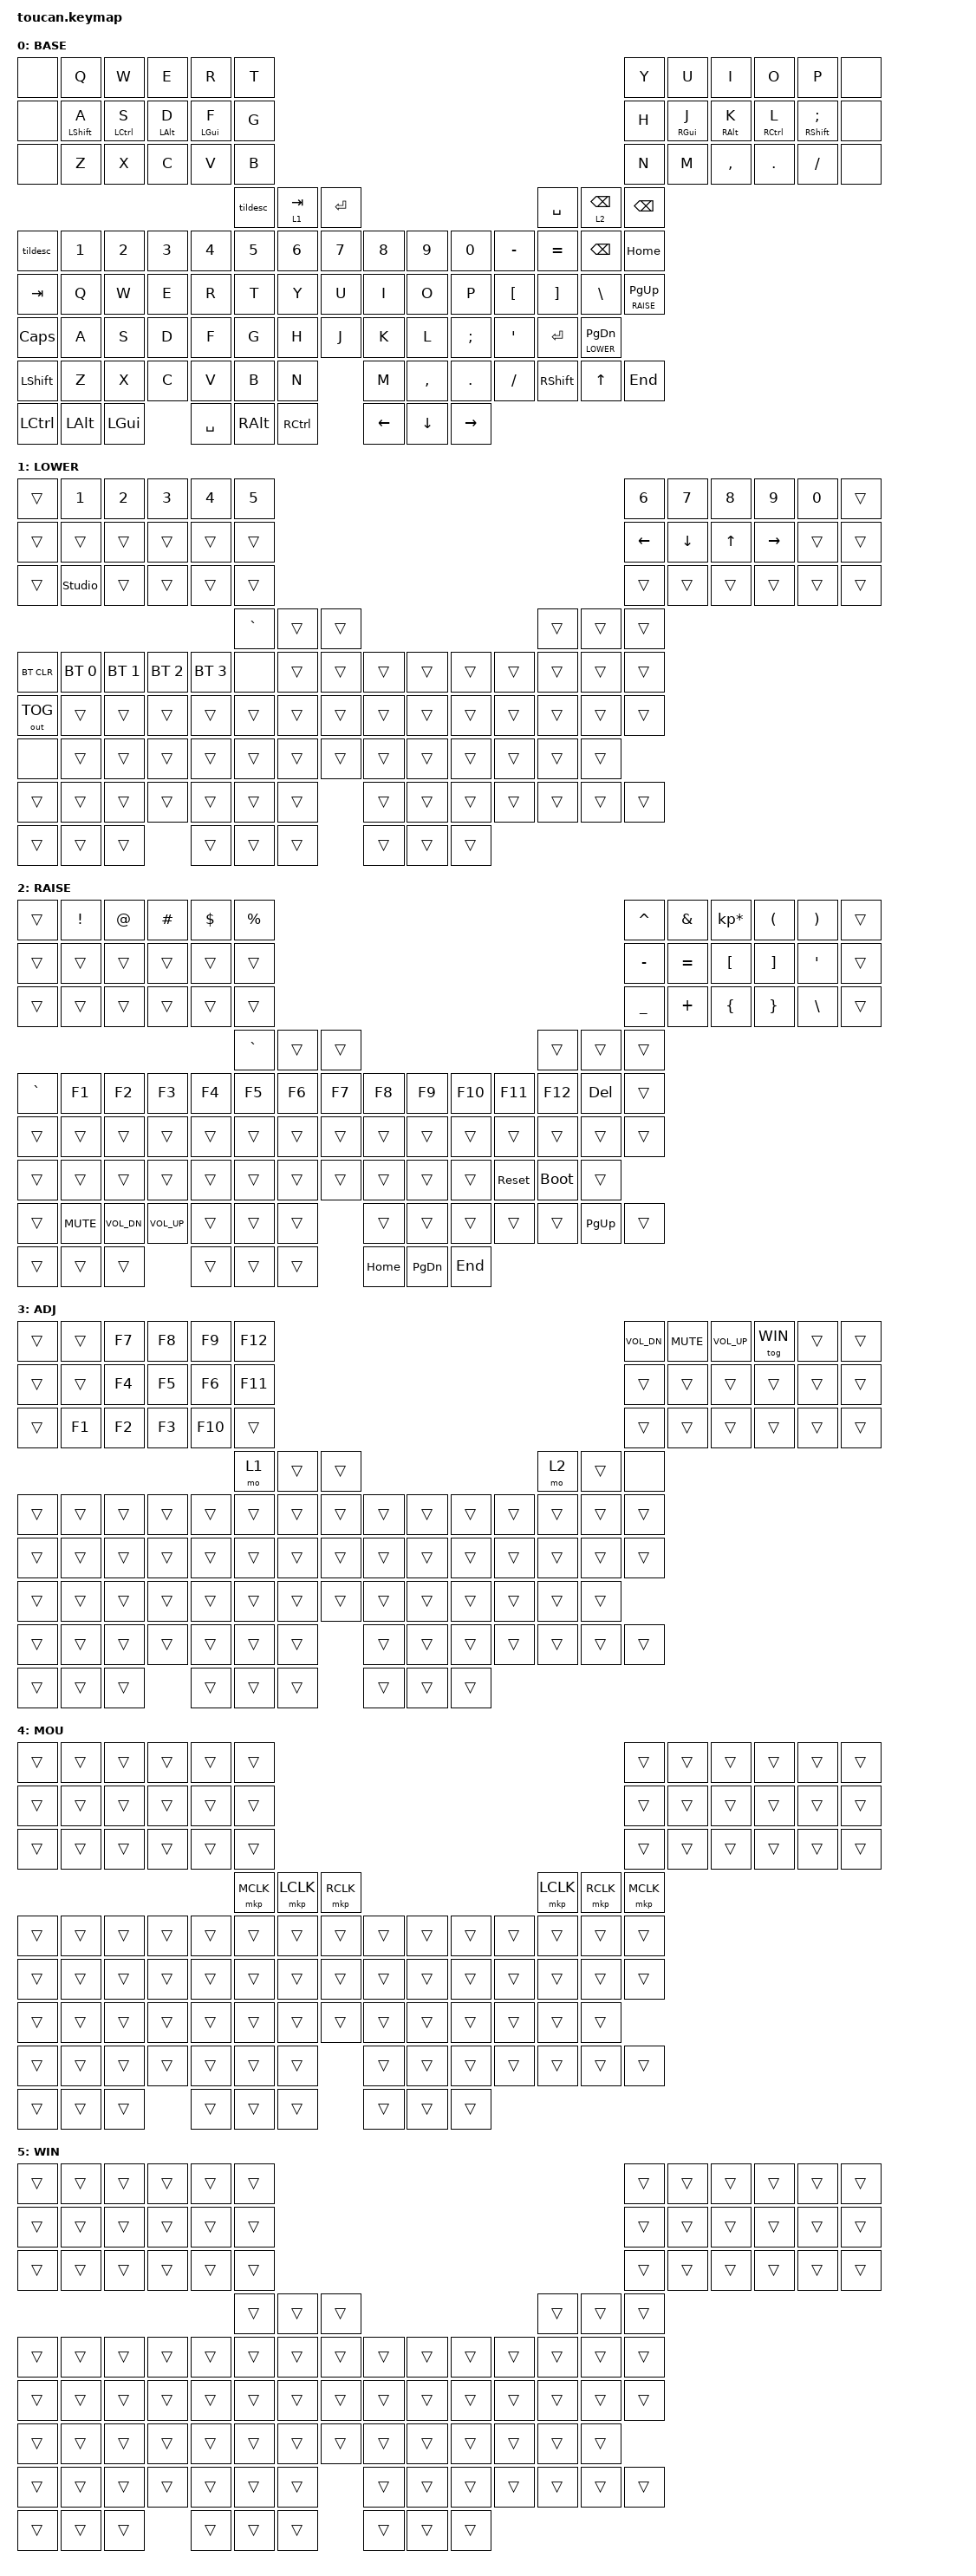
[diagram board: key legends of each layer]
#include <behaviors.dtsi>
#include <dt-bindings/zmk/keys.h>
#include <dt-bindings/zmk/bt.h>
#include <dt-bindings/zmk/outputs.h>

// Adding pointing.h to be able to right and middle click
// https://zmk.dev/docs/keymaps/behaviors/mouse-emulation
#include <dt-bindings/zmk/pointing.h>

#define BASE  0
#define LOWER 1
#define RAISE 2
#define ADJ   3
// Held automatically while a finger rests on the trackpad (is_touching_processor).
#define MOU   4
// Sticky toggle: swaps the trackpad's zoom/swipe shortcuts from macOS to Windows/Linux
// via the win_mode override on trackpad_listener. Otherwise transparent.
#define WIN   5


#define KEYS_L            0 1 2 3 4 5 12 13 14 15 16 17 24 25 26 27 28 29
#define KEYS_R            6 7 8 9 10 11 18 19 20 21 22 23 30 31 32 33 34 35
#define THUMBS            36 37 38 39 40 41
#define HRM_PRIOR_IDLE_MS 75

&lt {
  tapping-term-ms = <240>;
  flavor = "balanced";
  quick-tap-ms = <150>;
};

&mt {
  tapping-term-ms = <240>;
  flavor = "balanced";
  quick-tap-ms = <150>;
};

/ {
    conditional_layers {
        compatible = "zmk,conditional-layers";
        tri_layer {
            if-layers = <1 2>;
            then-layer = <3>;
        };
    };

    behaviors {
      // Testing urob's timeless home-row mods:
      // https://github.com/urob/zmk-config#timeless-homerow-mods
      // Cross-hand shortcuts can resolve immediately; same-hand shortcuts still
      // require holding past tapping-term-ms before pressing the next key.
      hrm_l: hrm_l {
        compatible = "zmk,behavior-hold-tap";
        #binding-cells = <2>;
        // How long a plain hold waits before becoming the modifier.
        // Cross-hand shortcuts can still resolve sooner via balanced + hold-trigger-key-positions.
        tapping-term-ms = <240>;
        bindings = <&kp>, <&kp>;
        flavor = "balanced";
        // If this HRM is tapped and quickly pressed again, keep the second press as a tap.
        // Useful for repeating letters without the second press becoming the modifier.
        quick-tap-ms = <150>;
        // If pressed within this window after a normal key, force a tap so fast typing stays immediate.
        // Lower this if intended HRM shifts/mods are blocked while typing quickly;
        // raise it if fast rolls accidentally trigger modifiers.
        require-prior-idle-ms = <HRM_PRIOR_IDLE_MS>;
        hold-trigger-key-positions = <KEYS_R THUMBS>;
        hold-trigger-on-release;
      };

      hrm_r: hrm_r {
        compatible = "zmk,behavior-hold-tap";
        #binding-cells = <2>;
        tapping-term-ms = <240>;
        bindings = <&kp>, <&kp>;
        flavor = "balanced";
        quick-tap-ms = <150>;
        require-prior-idle-ms = <HRM_PRIOR_IDLE_MS>;
        hold-trigger-key-positions = <KEYS_L THUMBS>;
        hold-trigger-on-release;
      };

      // Alt+Esc sends Alt+F4 (close window; Shut Down dialog on the Windows desktop).
      // keep-mods leaves Alt held, otherwise mod-morph would mask it and send bare F4.
      esc_altf4: esc_alt_f4 {
        compatible = "zmk,behavior-mod-morph";
        #binding-cells = <0>;
        bindings = <&kp ESC>, <&kp F4>;
        mods = <(MOD_LALT|MOD_RALT)>;
        keep-mods = <(MOD_LALT|MOD_RALT)>;
      };

      // GUI/Shift+Esc gives ~; otherwise falls through to esc_altf4.
      tildesc: tilde_escape {
        compatible = "zmk,behavior-mod-morph";
        #binding-cells = <0>;
        bindings = <&esc_altf4>, <&kp TILDE>;
        mods = <(MOD_LGUI|MOD_LSFT|MOD_RGUI|MOD_RSFT)>;
      };
    };

    keymap {
        compatible = "zmk,keymap";

        base {
            display-name = "BASE";
            bindings = <
                &none  &kp Q          &kp W           &kp E         &kp R         &kp T           &kp Y     &kp U         &kp I         &kp O           &kp P             &none
                &none  &hrm_l LSHFT A &hrm_l LCTRL S  &hrm_l LALT D &hrm_l LGUI F &kp G           &kp H     &hrm_r RGUI J &hrm_r RALT K &hrm_r RCTRL L  &hrm_r RSHFT SEMI &none
                &none  &kp Z          &kp X           &kp C         &kp V         &kp B           &kp N     &kp M         &kp COMMA     &kp DOT         &kp FSLH          &none
                                                      &tildesc      &lt 1 TAB     &kp RET         &kp SPACE &lt 2 BSPC    &kp BSPC
                // Tofu65 (positions 42-108). Right column: menu=Home, raise=PgUp/RAISE, lower=PgDn/LOWER, func=End.
                &tildesc  &kp N1 &kp N2 &kp N3 &kp N4 &kp N5 &kp N6 &kp N7 &kp N8 &kp N9 &kp N0 &kp MINUS &kp EQUAL &kp BSPC &kp HOME
                &kp TAB   &kp Q  &kp W  &kp E  &kp R  &kp T  &kp Y  &kp U  &kp I  &kp O  &kp P  &kp LBKT &kp RBKT &kp BSLH &lt RAISE PG_UP
                &kp CLCK  &kp A  &kp S  &kp D  &kp F  &kp G  &kp H  &kp J  &kp K  &kp L  &kp SEMI &kp SQT &kp ENTER &lt LOWER PG_DN
                &kp LSHFT &kp Z  &kp X  &kp C  &kp V  &kp B  &kp N  &kp M  &kp COMMA &kp DOT &kp FSLH &kp RSHFT &kp UP &kp END
                &kp LCTRL &kp LALT &kp LGUI &kp SPACE &kp RALT &kp RCTRL &kp LEFT &kp DOWN &kp RIGHT
            >;
        };

        // Tofu65 positions hold the system keys (BT profiles, output toggle), reached by holding the Tofu65's lower key.
        lower {
            display-name = "LOWER";
            bindings = <
                &trans  &kp N1         &kp N2   &kp N3    &kp N4  &kp N5           &kp N6   &kp N7   &kp N8  &kp N9     &kp N0  &trans
                &trans  &trans         &trans   &trans    &trans  &trans           &kp LEFT &kp DOWN &kp UP  &kp RIGHT  &trans  &trans
                &trans  &studio_unlock &trans   &trans    &trans  &trans           &trans   &trans   &trans  &trans     &trans  &trans
                                                &kp GRAVE &trans  &trans           &trans   &trans   &trans
                // Tofu65 (positions 42-108). Keys 1-4 select the dongle's host profiles 0-3 (BT_MAX_PAIRED 7 - 3 peripherals = 4).
                &bt BT_CLR &bt BT_SEL 0 &bt BT_SEL 1 &bt BT_SEL 2 &bt BT_SEL 3 &none &trans &trans &trans &trans &trans &trans &trans &trans &trans
                &out OUT_TOG &trans &trans &trans &trans &trans &trans &trans &trans &trans &trans &trans &trans &trans &trans
                &none &trans &trans &trans &trans &trans &trans &trans &trans &trans &trans &trans &trans &trans
                &trans &trans &trans &trans &trans &trans &trans &trans &trans &trans &trans &trans &trans &trans
                &trans &trans &trans &trans &trans &trans &trans &trans &trans
            >;
        };

        // Tofu65 positions hold the Fn keys (F-row, media, reset/bootloader, nav on arrows), reached by holding the Tofu65's raise key.
        raise {
            display-name = "RAISE";
            bindings = <
                &trans  &kp EXCL  &kp AT  &kp HASH  &kp DLLR  &kp PRCNT         &kp CARET  &kp AMPS   &kp KP_MULTIPLY  &kp LPAR  &kp RPAR  &trans
                &trans  &trans    &trans  &trans    &trans    &trans            &kp MINUS  &kp EQUAL  &kp LBKT         &kp RBKT  &kp SQT   &trans
                &trans  &trans    &trans  &trans    &trans    &trans            &kp UNDER  &kp PLUS   &kp LBRC         &kp RBRC  &kp BSLH  &trans
                                          &kp GRAVE &trans    &trans            &trans     &trans     &trans
                // Tofu65 (positions 42-108)
                &kp GRAVE &kp F1 &kp F2 &kp F3 &kp F4 &kp F5 &kp F6 &kp F7 &kp F8 &kp F9 &kp F10 &kp F11 &kp F12 &kp DEL &trans
                &trans &trans &trans &trans &trans &trans &trans &trans &trans &trans &trans &trans &trans &trans &trans
                &trans &trans &trans &trans &trans &trans &trans &trans &trans &trans &trans &sys_reset &bootloader &trans
                &trans &kp C_MUTE &kp C_VOL_DN &kp C_VOL_UP &trans &trans &trans &trans &trans &trans &trans &trans &kp PG_UP &trans
                &trans &trans &trans &trans &trans &trans &kp HOME &kp PG_DN &kp END
            >;
        };

        adj {
            display-name = "ADJ";
            bindings = <
                &trans  &trans  &kp F7  &kp F8  &kp F9   &kp F12            &kp C_VOL_DN  &kp C_MUTE  &kp C_VOL_UP  &tog WIN  &trans  &trans
                &trans  &trans  &kp F4  &kp F5  &kp F6   &kp F11            &trans        &trans      &trans        &trans  &trans  &trans
                &trans  &kp F1  &kp F2  &kp F3  &kp F10  &trans             &trans        &trans      &trans        &trans  &trans  &trans
                                        &mo 1   &trans   &trans             &mo 2         &trans      &none
                // Tofu65 (positions 42-108)
                &trans &trans &trans &trans &trans &trans &trans &trans &trans &trans &trans &trans &trans &trans &trans
                &trans &trans &trans &trans &trans &trans &trans &trans &trans &trans &trans &trans &trans &trans &trans
                &trans &trans &trans &trans &trans &trans &trans &trans &trans &trans &trans &trans &trans &trans
                &trans &trans &trans &trans &trans &trans &trans &trans &trans &trans &trans &trans &trans &trans
                &trans &trans &trans &trans &trans &trans &trans &trans &trans
            >;
        };

        // Held while touching the trackpad, so the thumb keys become mouse buttons.
        mouse {
            display-name = "MOU";
            bindings = <
                &trans  &trans  &trans  &trans  &trans  &trans            &trans  &trans  &trans  &trans  &trans  &trans
                &trans  &trans  &trans  &trans  &trans  &trans            &trans  &trans  &trans  &trans  &trans  &trans
                &trans  &trans  &trans  &trans  &trans  &trans            &trans  &trans  &trans  &trans  &trans  &trans
                                    &mkp MCLK  &mkp LCLK  &mkp RCLK       &mkp LCLK  &mkp RCLK  &mkp MCLK
                // Tofu65 (positions 42-108)
                &trans &trans &trans &trans &trans &trans &trans &trans &trans &trans &trans &trans &trans &trans &trans
                &trans &trans &trans &trans &trans &trans &trans &trans &trans &trans &trans &trans &trans &trans &trans
                &trans &trans &trans &trans &trans &trans &trans &trans &trans &trans &trans &trans &trans &trans
                &trans &trans &trans &trans &trans &trans &trans &trans &trans &trans &trans &trans &trans &trans
                &trans &trans &trans &trans &trans &trans &trans &trans &trans
            >;
        };

        // Fully transparent. Exists only so trackpad_listener's win_mode override has a
        // layer to key off; toggled with &tog WIN from ADJ. Not persisted across reboots.
        win {
            display-name = "WIN";
            bindings = <
                &trans  &trans  &trans  &trans  &trans  &trans            &trans  &trans  &trans  &trans  &trans  &trans
                &trans  &trans  &trans  &trans  &trans  &trans            &trans  &trans  &trans  &trans  &trans  &trans
                &trans  &trans  &trans  &trans  &trans  &trans            &trans  &trans  &trans  &trans  &trans  &trans
                                        &trans  &trans  &trans            &trans  &trans  &trans
                // Tofu65 (positions 42-108)
                &trans &trans &trans &trans &trans &trans &trans &trans &trans &trans &trans &trans &trans &trans &trans
                &trans &trans &trans &trans &trans &trans &trans &trans &trans &trans &trans &trans &trans &trans &trans
                &trans &trans &trans &trans &trans &trans &trans &trans &trans &trans &trans &trans &trans &trans
                &trans &trans &trans &trans &trans &trans &trans &trans &trans &trans &trans &trans &trans &trans
                &trans &trans &trans &trans &trans &trans &trans &trans &trans
            >;
        };
    };
};
